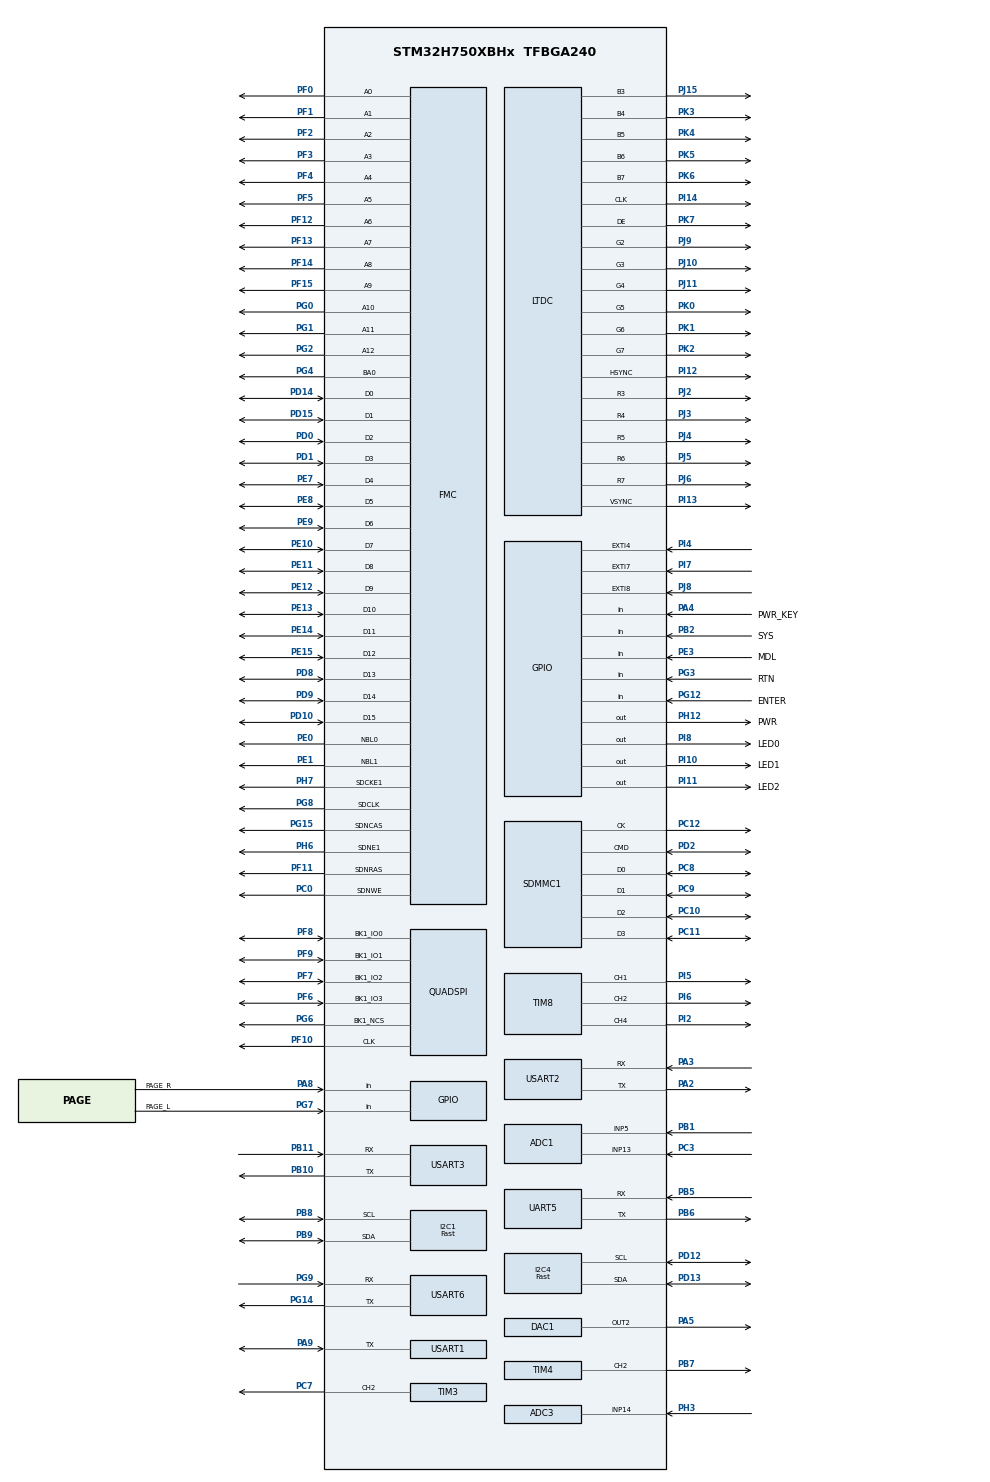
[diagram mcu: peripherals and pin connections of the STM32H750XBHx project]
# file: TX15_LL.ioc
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ADC1.Channel-0\#ChannelRegularConversion=ADC_CHANNEL_5
ADC1.NbrOfConversionFlag=1
ADC1.OffsetNumber-0\#ChannelRegularConversion=ADC_OFFSET_NONE
ADC1.OffsetSignedSaturation-0\#ChannelRegularConversion=DISABLE
ADC1.OversamplingMode=ENABLE
ADC1.Rank-0\#ChannelRegularConversion=1
ADC1.Ratio=16
ADC1.RightBitShift=ADC_RIGHTBITSHIFT_4
ADC1.SamplingTime-0\#ChannelRegularConversion=ADC_SAMPLETIME_1CYCLE_5
ADC1.master=1
ADC3.Channel-2\#ChannelRegularConversion=ADC_CHANNEL_14
ADC3.NbrOfConversionFlag=1
ADC3.OffsetNumber-2\#ChannelRegularConversion=ADC_OFFSET_NONE
ADC3.OffsetSignedSaturation-2\#ChannelRegularConversion=DISABLE
ADC3.Rank-2\#ChannelRegularConversion=1
ADC3.SamplingTime-2\#ChannelRegularConversion=ADC_SAMPLETIME_1CYCLE_5
CORTEX_M7.default_mode_Activation=1
DAC1.DAC_Channel-DAC_OUT2_ExtAndInt=DAC_CHANNEL_2
DAC1.DAC_Trigger-DAC_OUT2_ExtAndInt=DAC_TRIGGER_T6_TRGO
DMA2D.ColorMode=DMA2D_OUTPUT_RGB565
Dma.ADC1.2.Direction=DMA_PERIPH_TO_MEMORY
Dma.ADC1.2.EventEnable=DISABLE
Dma.ADC1.2.FIFOMode=DMA_FIFOMODE_DISABLE
Dma.ADC1.2.Instance=DMA1_Stream2
Dma.ADC1.2.MemDataAlignment=DMA_MDATAALIGN_HALFWORD
Dma.ADC1.2.MemInc=DMA_MINC_ENABLE
Dma.ADC1.2.Mode=DMA_NORMAL
Dma.ADC1.2.PeriphDataAlignment=DMA_PDATAALIGN_HALFWORD
Dma.ADC1.2.PeriphInc=DMA_PINC_DISABLE
Dma.ADC1.2.Polarity=HAL_DMAMUX_REQ_GEN_RISING
Dma.ADC1.2.Priority=DMA_PRIORITY_LOW
Dma.ADC1.2.RequestNumber=1
Dma.ADC1.2.SignalID=NONE
Dma.ADC1.2.SyncEnable=DISABLE
Dma.ADC1.2.SyncPolarity=HAL_DMAMUX_SYNC_NO_EVENT
Dma.ADC1.2.SyncRequestNumber=1
Dma.ADC1.2.SyncSignalID=NONE
Dma.ADC3.3.Direction=DMA_PERIPH_TO_MEMORY
Dma.ADC3.3.EventEnable=DISABLE
Dma.ADC3.3.FIFOMode=DMA_FIFOMODE_DISABLE
Dma.ADC3.3.Instance=DMA1_Stream3
Dma.ADC3.3.MemDataAlignment=DMA_MDATAALIGN_HALFWORD
Dma.ADC3.3.MemInc=DMA_MINC_ENABLE
Dma.ADC3.3.Mode=DMA_NORMAL
Dma.ADC3.3.PeriphDataAlignment=DMA_PDATAALIGN_HALFWORD
Dma.ADC3.3.PeriphInc=DMA_PINC_DISABLE
Dma.ADC3.3.Polarity=HAL_DMAMUX_REQ_GEN_RISING
Dma.ADC3.3.Priority=DMA_PRIORITY_LOW
Dma.ADC3.3.RequestNumber=1
Dma.ADC3.3.SignalID=NONE
Dma.ADC3.3.SyncEnable=DISABLE
Dma.ADC3.3.SyncPolarity=HAL_DMAMUX_SYNC_NO_EVENT
Dma.ADC3.3.SyncRequestNumber=1
Dma.ADC3.3.SyncSignalID=NONE
Dma.DAC1_CH2.4.Direction=DMA_MEMORY_TO_PERIPH
Dma.DAC1_CH2.4.EventEnable=DISABLE
Dma.DAC1_CH2.4.FIFOMode=DMA_FIFOMODE_DISABLE
Dma.DAC1_CH2.4.Instance=DMA1_Stream4
Dma.DAC1_CH2.4.MemDataAlignment=DMA_MDATAALIGN_BYTE
Dma.DAC1_CH2.4.MemInc=DMA_MINC_ENABLE
Dma.DAC1_CH2.4.Mode=DMA_NORMAL
Dma.DAC1_CH2.4.PeriphDataAlignment=DMA_PDATAALIGN_BYTE
Dma.DAC1_CH2.4.PeriphInc=DMA_PINC_DISABLE
Dma.DAC1_CH2.4.Polarity=HAL_DMAMUX_REQ_GEN_RISING
Dma.DAC1_CH2.4.Priority=DMA_PRIORITY_LOW
Dma.DAC1_CH2.4.RequestNumber=1
Dma.DAC1_CH2.4.SignalID=NONE
Dma.DAC1_CH2.4.SyncEnable=DISABLE
Dma.DAC1_CH2.4.SyncPolarity=HAL_DMAMUX_SYNC_NO_EVENT
Dma.DAC1_CH2.4.SyncRequestNumber=1
Dma.DAC1_CH2.4.SyncSignalID=NONE
Dma.Request0=TIM3_CH2
Dma.Request1=TIM8_CH4
Dma.Request2=ADC1
Dma.Request3=ADC3
Dma.Request4=DAC1_CH2
Dma.TIM3_CH2.0.Direction=DMA_PERIPH_TO_MEMORY
Dma.TIM3_CH2.0.EventEnable=DISABLE
Dma.TIM3_CH2.0.FIFOMode=DMA_FIFOMODE_DISABLE
Dma.TIM3_CH2.0.Instance=DMA1_Stream0
Dma.TIM3_CH2.0.MemDataAlignment=DMA_MDATAALIGN_HALFWORD
Dma.TIM3_CH2.0.MemInc=DMA_MINC_ENABLE
Dma.TIM3_CH2.0.Mode=DMA_NORMAL
Dma.TIM3_CH2.0.PeriphDataAlignment=DMA_PDATAALIGN_HALFWORD
Dma.TIM3_CH2.0.PeriphInc=DMA_PINC_DISABLE
Dma.TIM3_CH2.0.Polarity=HAL_DMAMUX_REQ_GEN_RISING
Dma.TIM3_CH2.0.Priority=DMA_PRIORITY_LOW
Dma.TIM3_CH2.0.RequestNumber=1
Dma.TIM3_CH2.0.SignalID=NONE
Dma.TIM3_CH2.0.SyncEnable=DISABLE
Dma.TIM3_CH2.0.SyncPolarity=HAL_DMAMUX_SYNC_NO_EVENT
Dma.TIM3_CH2.0.SyncRequestNumber=1
Dma.TIM3_CH2.0.SyncSignalID=NONE
Dma.TIM8_CH4.1.Direction=DMA_PERIPH_TO_MEMORY
Dma.TIM8_CH4.1.EventEnable=DISABLE
Dma.TIM8_CH4.1.FIFOMode=DMA_FIFOMODE_DISABLE
Dma.TIM8_CH4.1.Instance=DMA1_Stream1
Dma.TIM8_CH4.1.MemDataAlignment=DMA_MDATAALIGN_HALFWORD
Dma.TIM8_CH4.1.MemInc=DMA_MINC_ENABLE
Dma.TIM8_CH4.1.Mode=DMA_NORMAL
Dma.TIM8_CH4.1.PeriphDataAlignment=DMA_PDATAALIGN_HALFWORD
Dma.TIM8_CH4.1.PeriphInc=DMA_PINC_DISABLE
Dma.TIM8_CH4.1.Polarity=HAL_DMAMUX_REQ_GEN_RISING
Dma.TIM8_CH4.1.Priority=DMA_PRIORITY_LOW
Dma.TIM8_CH4.1.RequestNumber=1
Dma.TIM8_CH4.1.SignalID=NONE
Dma.TIM8_CH4.1.SyncEnable=DISABLE
Dma.TIM8_CH4.1.SyncPolarity=HAL_DMAMUX_SYNC_NO_EVENT
Dma.TIM8_CH4.1.SyncRequestNumber=1
Dma.TIM8_CH4.1.SyncSignalID=NONE
FREERTOS.Tasks01=defaultTask,24,128,StartDefaultTask,Default,NULL,Dynamic,NULL,NULL;LedTask,8,128,led_task,Default,NULL,Dynamic,NULL,NULL
I2C1.I2C_Speed_Mode=I2C_Fast
I2C1.Timing=0x00B03FDB
I2C4.I2C_Speed_Mode=I2C_Fast
I2C4.Timing=0x00B03FDB
LTDC.ActiveW=320
LTDC.Alpha_L0=255
LTDC.HBP=20
LTDC.HFP=40
LTDC.HSync=6
LTDC.Layers=0
LTDC.PixelFormat_L0=LTDC_PIXEL_FORMAT_RGB565
LTDC.VBP=10
LTDC.VFP=10
LTDC.VSync=2
LTDC.WindowX1_L0=320
LTDC.WindowY1_L0=480
Mcu.Family=STM32H7
Mcu.Name=STM32H750XBHx
Mcu.Package=TFBGA240
Mdma.MDMA_Channel0.Request0=SDMMC1_DMA_ENDBUFFER
Mdma.MDMA_Channel0.RequestsNb=1
Mdma.MDMA_Channel0.SDMMC1_DMA_ENDBUFFER.0.BlockCount=4
Mdma.MDMA_Channel0.SDMMC1_DMA_ENDBUFFER.0.BlockDataLength=512
Mdma.MDMA_Channel0.SDMMC1_DMA_ENDBUFFER.0.BufferTransferLength=2048
Mdma.MDMA_Channel0.SDMMC1_DMA_ENDBUFFER.0.CircularMode=MDMA_LINEAR_LIST
Mdma.MDMA_Channel0.SDMMC1_DMA_ENDBUFFER.0.DataAlignment=MDMA_DATAALIGN_PACKENABLE
Mdma.MDMA_Channel0.SDMMC1_DMA_ENDBUFFER.0.DestBlockAddressOffset=0
Mdma.MDMA_Channel0.SDMMC1_DMA_ENDBUFFER.0.DestBurst=MDMA_DEST_BURST_4BEATS
Mdma.MDMA_Channel0.SDMMC1_DMA_ENDBUFFER.0.DestDataSize=MDMA_DEST_DATASIZE_WORD
Mdma.MDMA_Channel0.SDMMC1_DMA_ENDBUFFER.0.DestinationInc=MDMA_DEST_INC_WORD
Mdma.MDMA_Channel0.SDMMC1_DMA_ENDBUFFER.0.DstAddress=0
Mdma.MDMA_Channel0.SDMMC1_DMA_ENDBUFFER.0.Endianness=MDMA_LITTLE_ENDIANNESS_PRESERVE
Mdma.MDMA_Channel0.SDMMC1_DMA_ENDBUFFER.0.Instance=MDMA_Channel0
Mdma.MDMA_Channel0.SDMMC1_DMA_ENDBUFFER.0.MaskAddress=0
Mdma.MDMA_Channel0.SDMMC1_DMA_ENDBUFFER.0.MaskData=0
Mdma.MDMA_Channel0.SDMMC1_DMA_ENDBUFFER.0.Priority=MDMA_PRIORITY_LOW
Mdma.MDMA_Channel0.SDMMC1_DMA_ENDBUFFER.0.Rank=First
Mdma.MDMA_Channel0.SDMMC1_DMA_ENDBUFFER.0.SourceBlockAddressOffset=0
Mdma.MDMA_Channel0.SDMMC1_DMA_ENDBUFFER.0.SourceBurst=MDMA_SOURCE_BURST_4BEATS
Mdma.MDMA_Channel0.SDMMC1_DMA_ENDBUFFER.0.SourceDataSize=MDMA_SRC_DATASIZE_WORD
Mdma.MDMA_Channel0.SDMMC1_DMA_ENDBUFFER.0.SourceInc=MDMA_SRC_INC_WORD
Mdma.MDMA_Channel0.SDMMC1_DMA_ENDBUFFER.0.SrcAddress=0
Mdma.MDMA_Channel0.SDMMC1_DMA_ENDBUFFER.0.TransferTriggerMode=MDMA_BUFFER_TRANSFER
Mdma.RequestSet0=MDMA_Channel0
Mdma.RequestSetsNb=1
NVIC.DMA1_Stream0_IRQn=true\:5\:0\:false\:false\:true\:true\:false\:true\:true
NVIC.DMA1_Stream1_IRQn=true\:5\:0\:false\:false\:true\:true\:false\:true\:true
NVIC.DMA1_Stream2_IRQn=true\:5\:0\:false\:false\:true\:true\:false\:true\:true
NVIC.DMA1_Stream3_IRQn=true\:5\:0\:false\:false\:true\:true\:false\:true\:true
NVIC.DMA1_Stream4_IRQn=true\:5\:0\:false\:false\:true\:true\:false\:true\:true
NVIC.EXTI4_IRQn=true\:5\:0\:false\:false\:true\:true\:true\:true\:true
NVIC.EXTI9_5_IRQn=true\:5\:0\:false\:false\:true\:true\:true\:true\:true
NVIC.LTDC_IRQn=true\:5\:0\:false\:false\:true\:true\:true\:true\:true
NVIC.MDMA_IRQn=true\:5\:0\:false\:false\:true\:true\:false\:true\:true
NVIC.PriorityGroup=NVIC_PRIORITYGROUP_4
NVIC.TIM17_IRQn=true\:5\:0\:false\:false\:true\:true\:true\:true\:true
NVIC.TIM1_UP_IRQn=true\:15\:0\:false\:false\:true\:false\:false\:true\:true
NVIC.TIM6_DAC_IRQn=true\:5\:0\:false\:false\:true\:true\:true\:true\:true
NVIC.TIM8_CC_IRQn=true\:5\:0\:false\:false\:true\:true\:true\:true\:true
NVIC.TIM8_UP_TIM13_IRQn=true\:5\:0\:false\:false\:true\:true\:true\:true\:true
NVIC.TimeBase=TIM1_UP_IRQn
NVIC.TimeBaseIP=TIM1
PA10.Signal=S_TIM1_CH3
PA2.Mode=Asynchronous
PA2.Signal=USART2_TX
PA3.Mode=Asynchronous
PA3.Signal=USART2_RX
PA4.GPIO_Label=PWR_KEY
PA4.Signal=GPIO_Input
PA5.Signal=COMP_DAC12_group
PA8.GPIO_Label=PAGE_R
PA8.Signal=GPIO_Input
PA9.Mode=Half_duplex(single_wire_mode)
PA9.Signal=USART1_TX
PB1.Signal=ADCx_INP5
PB10.Mode=Asynchronous
PB10.Signal=USART3_TX
PB11.Mode=Asynchronous
PB11.Signal=USART3_RX
PB2.GPIO_Label=SYS
PB2.Signal=GPIO_Input
PB5.Mode=Asynchronous
PB5.Signal=UART5_RX
PB6.Mode=Asynchronous
PB6.Signal=UART5_TX
PB7.Signal=S_TIM4_CH2
PB8.Mode=I2C
PB8.Signal=I2C1_SCL
PB9.Mode=I2C
PB9.Signal=I2C1_SDA
PC0.Signal=FMC_SDNWE
PC1.Signal=ADCx_INP11
PC10.Mode=SD_4_bits_Wide_bus
PC10.Signal=SDMMC1_D2
PC11.Mode=SD_4_bits_Wide_bus
PC11.Signal=SDMMC1_D3
PC12.Mode=SD_4_bits_Wide_bus
PC12.Signal=SDMMC1_CK
PC2.Signal=ADCx_INP12
PC3.Signal=ADCx_INP13
PC7.Signal=S_TIM3_CH2
PC8.Mode=SD_4_bits_Wide_bus
PC8.Signal=SDMMC1_D0
PC9.Mode=SD_4_bits_Wide_bus
PC9.Signal=SDMMC1_D1
PD0.Signal=FMC_D2_DA2
PD1.Signal=FMC_D3_DA3
PD10.Signal=FMC_D15_DA15
PD12.Mode=I2C
PD12.Signal=I2C4_SCL
PD13.Mode=I2C
PD13.Signal=I2C4_SDA
PD14.Signal=FMC_D0_DA0
PD15.Signal=FMC_D1_DA1
PD2.Mode=SD_4_bits_Wide_bus
PD2.Signal=SDMMC1_CMD
PD8.Signal=FMC_D13_DA13
PD9.Signal=FMC_D14_DA14
PE0.Signal=FMC_NBL0
PE1.Signal=FMC_NBL1
PE10.Signal=FMC_D7_DA7
PE11.Signal=FMC_D8_DA8
PE12.Signal=FMC_D9_DA9
PE13.Signal=FMC_D10_DA10
PE14.Signal=FMC_D11_DA11
PE15.Signal=FMC_D12_DA12
PE3.GPIO_Label=MDL
PE3.Signal=GPIO_Input
PE7.Signal=FMC_D4_DA4
PE8.Signal=FMC_D5_DA5
PE9.Signal=FMC_D6_DA6
PF0.Signal=FMC_A0
PF1.Signal=FMC_A1
PF10.Mode=Single Bank 1
PF10.Signal=QUADSPI_CLK
PF11.Signal=FMC_SDNRAS
PF12.Signal=FMC_A6
PF13.Signal=FMC_A7
PF14.Signal=FMC_A8
PF15.Signal=FMC_A9
PF2.Signal=FMC_A2
PF3.Signal=FMC_A3
PF4.Signal=FMC_A4
PF5.Signal=FMC_A5
PF6.Mode=Single Bank 1
PF6.Signal=QUADSPI_BK1_IO3
PF7.Mode=Single Bank 1
PF7.Signal=QUADSPI_BK1_IO2
PF8.Mode=Single Bank 1
PF8.Signal=QUADSPI_BK1_IO0
PF9.Mode=Single Bank 1
PF9.Signal=QUADSPI_BK1_IO1
PG0.Signal=FMC_A10
PG1.Signal=FMC_A11
PG12.GPIO_Label=ENTER
PG12.Signal=GPIO_Input
PG14.Mode=Asynchronous
PG14.Signal=USART6_TX
PG15.Signal=FMC_SDNCAS
PG2.Signal=FMC_A12
PG3.GPIO_Label=RTN
PG3.Signal=GPIO_Input
PG4.Signal=FMC_A14_BA0
PG5.Signal=FMC_A15_BA1
PG6.Mode=Single Bank 1
PG6.Signal=QUADSPI_BK1_NCS
PG7.GPIO_Label=PAGE_L
PG7.Signal=GPIO_Input
PG8.Signal=FMC_SDCLK
PG9.Mode=Asynchronous
PG9.Signal=USART6_RX
PH0-OSC_IN\ (PH0).Mode=HSE-External-Clock-Source
PH0-OSC_IN\ (PH0).Signal=RCC_OSC_IN
PH12.GPIO_Label=PWR
PH12.Signal=GPIO_Output
PH3.Mode=IN14-Single-Ended
PH3.Signal=ADC3_INP14
PH6.Mode=SdramChipSelect2_1
PH6.Signal=FMC_SDNE1
PH7.Mode=SdramChipSelect2_1
PH7.Signal=FMC_SDCKE1
PI10.GPIO_Label=LED1
PI10.Signal=GPIO_Output
PI11.GPIO_Label=LED2
PI11.Signal=GPIO_Output
PI12.Mode=RGB565
PI12.Signal=LTDC_HSYNC
PI13.Mode=RGB565
PI13.Signal=LTDC_VSYNC
PI14.Mode=RGB565
PI14.Signal=LTDC_CLK
PI2.Signal=S_TIM8_CH4
PI4.Signal=GPXTI4
PI5.Signal=S_TIM8_CH1
PI6.Signal=S_TIM8_CH2
PI7.Signal=GPXTI7
PI8.GPIO_Label=LED0
PI8.Signal=GPIO_Output
PJ1.Signal=LTDC_R2
PJ10.Mode=RGB565
PJ10.Signal=LTDC_G3
PJ11.Mode=RGB565
PJ11.Signal=LTDC_G4
PJ14.Signal=LTDC_B2
PJ15.Mode=RGB565
PJ15.Signal=LTDC_B3
PJ2.Mode=RGB565
PJ2.Signal=LTDC_R3
PJ3.Mode=RGB565
PJ3.Signal=LTDC_R4
PJ4.Mode=RGB565
PJ4.Signal=LTDC_R5
PJ5.Mode=RGB565
PJ5.Signal=LTDC_R6
PJ6.Mode=RGB565
PJ6.Signal=LTDC_R7
PJ8.Signal=GPXTI8
PJ9.Mode=RGB565
PJ9.Signal=LTDC_G2
PK0.Mode=RGB565
PK0.Signal=LTDC_G5
PK1.Mode=RGB565
PK1.Signal=LTDC_G6
PK2.Mode=RGB565
PK2.Signal=LTDC_G7
PK3.Mode=RGB565
PK3.Signal=LTDC_B4
PK4.Mode=RGB565
PK4.Signal=LTDC_B5
PK5.Mode=RGB565
PK5.Signal=LTDC_B6
PK6.Mode=RGB565
PK6.Signal=LTDC_B7
PK7.Mode=RGB565
PK7.Signal=LTDC_DE
ProjectManager.HeapSize=0x200
ProjectManager.StackSize=0x400
ProjectManager.TargetToolchain=MDK-ARM V5.32
QUADSPI.ClockPrescaler=2
QUADSPI.FifoThreshold=8
QUADSPI.FlashSize=23
RCC.ADCCLockSelection=RCC_ADCCLKSOURCE_CLKP
RCC.ADCFreq_Value=64000000
RCC.APB1Freq_Value=120000000
RCC.APB2Freq_Value=120000000
RCC.APB3Freq_Value=120000000
RCC.APB4Freq_Value=120000000
RCC.CortexFreq_Value=480000000
RCC.D1PPRE=RCC_APB3_DIV2
RCC.D2PPRE1=RCC_APB1_DIV2
RCC.D2PPRE2=RCC_APB2_DIV2
RCC.D3PPRE=RCC_APB4_DIV2
RCC.DIVM1=3
RCC.DIVM2=24
RCC.DIVM3=1
RCC.DIVN1=60
RCC.DIVN2=96
RCC.DIVN3=4
RCC.DIVP2=26
RCC.DIVQ1=20
RCC.DIVQ2=4
RCC.DIVR2=1
RCC.DIVR3=18
RCC.EnbaleCSS=false
RCC.FMCCLockSelection=RCC_FMCCLKSOURCE_PLL2
RCC.HCLKFreq_Value=240000000
RCC.HPRE=RCC_HCLK_DIV2
RCC.HSE_VALUE=48000000
RCC.PLL2FRACN=0
RCC.PLL2_VCI_Range-AdvancedSettings=RCC_PLL2VCIRANGE_0
RCC.PLL2_VCO_SEL-AdvancedSettings=RCC_PLL2VCOWIDE
RCC.PLL3FRACN=0
RCC.PLL3_VCI_Range-AdvancedSettings=RCC_PLL3VCIRANGE_0
RCC.PLLFRACN=0
RCC.PLLSourceVirtual=RCC_PLLSOURCE_HSE
RCC.RCC_RTC_Clock_Source_FROM_HSE=RCC_RTCCLKSOURCE_HSE_DIV48
RCC.SYSCLKFreq_VALUE=480000000
RCC.SYSCLKSource=RCC_SYSCLKSOURCE_PLLCLK
RCC.USBFreq_Value=48000000
RTC.WakeUpClock-WakeUp=RTC_WAKEUPCLOCK_CK_SPRE_16BITS
SDMMC1.ClockDiv=2
SH.ADCx_INP11.0=ADC1_INP11
SH.ADCx_INP12.0=ADC1_INP12
SH.ADCx_INP13.0=ADC1_INP13,IN13-Single-Ended
SH.ADCx_INP5.0=ADC1_INP5,IN5-Single-Ended
SH.COMP_DAC12_group.0=DAC1_OUT2,DAC_OUT2_ExtAndInt
SH.FMC_A0.0=FMC_A0,13b-sda1
SH.FMC_A1.0=FMC_A1,13b-sda1
SH.FMC_A10.0=FMC_A10,13b-sda1
SH.FMC_A11.0=FMC_A11,13b-sda1
SH.FMC_A12.0=FMC_A12,13b-sda1
SH.FMC_A14_BA0.0=FMC_BA0,TwoSdramBanks1
SH.FMC_A15_BA1.0=FMC_BA1
SH.FMC_A2.0=FMC_A2,13b-sda1
SH.FMC_A3.0=FMC_A3,13b-sda1
SH.FMC_A4.0=FMC_A4,13b-sda1
SH.FMC_A5.0=FMC_A5,13b-sda1
SH.FMC_A6.0=FMC_A6,13b-sda1
SH.FMC_A7.0=FMC_A7,13b-sda1
SH.FMC_A8.0=FMC_A8,13b-sda1
SH.FMC_A9.0=FMC_A9,13b-sda1
SH.FMC_D0_DA0.0=FMC_D0,sd-16b-d1
SH.FMC_D10_DA10.0=FMC_D10,sd-16b-d1
SH.FMC_D11_DA11.0=FMC_D11,sd-16b-d1
SH.FMC_D12_DA12.0=FMC_D12,sd-16b-d1
SH.FMC_D13_DA13.0=FMC_D13,sd-16b-d1
SH.FMC_D14_DA14.0=FMC_D14,sd-16b-d1
SH.FMC_D15_DA15.0=FMC_D15,sd-16b-d1
SH.FMC_D1_DA1.0=FMC_D1,sd-16b-d1
SH.FMC_D2_DA2.0=FMC_D2,sd-16b-d1
SH.FMC_D3_DA3.0=FMC_D3,sd-16b-d1
SH.FMC_D4_DA4.0=FMC_D4,sd-16b-d1
SH.FMC_D5_DA5.0=FMC_D5,sd-16b-d1
SH.FMC_D6_DA6.0=FMC_D6,sd-16b-d1
SH.FMC_D7_DA7.0=FMC_D7,sd-16b-d1
SH.FMC_D8_DA8.0=FMC_D8,sd-16b-d1
SH.FMC_D9_DA9.0=FMC_D9,sd-16b-d1
SH.FMC_NBL0.0=FMC_NBL0,Sd2ByteEnable1
SH.FMC_NBL1.0=FMC_NBL1,Sd2ByteEnable1
SH.FMC_SDCLK.0=FMC_SDCLK,13b-sda1
SH.FMC_SDNCAS.0=FMC_SDNCAS,13b-sda1
SH.FMC_SDNRAS.0=FMC_SDNRAS,13b-sda1
SH.FMC_SDNWE.0=FMC_SDNWE,13b-sda1
SH.S_TIM1_CH3.0=TIM1_CH3
SH.S_TIM3_CH2.0=TIM3_CH2,PWM Generation2 CH2
SH.S_TIM4_CH2.0=TIM4_CH2,PWM Generation2 CH2
SH.S_TIM8_CH1.0=TIM8_CH1,Output Compare1 CH1
SH.S_TIM8_CH2.0=TIM8_CH2,Output Compare2 CH2
SH.S_TIM8_CH4.0=TIM8_CH4,PWM Generation4 CH4
TIM17.Period=1000
TIM17.Prescaler=4
TIM3.Channel-PWM\ Generation2\ CH2=TIM_CHANNEL_2
TIM3.Prescaler=2
TIM4.Channel-PWM\ Generation2\ CH2=TIM_CHANNEL_2
TIM8.Channel-Output\ Compare1\ CH1=TIM_CHANNEL_1
TIM8.Channel-Output\ Compare2\ CH2=TIM_CHANNEL_2
TIM8.Channel-PWM\ Generation4\ CH4=TIM_CHANNEL_4
USART1.VirtualMode-Half_duplex(single_wire_mode)=VM_ASYNC
USART2.VirtualMode-Asynchronous=VM_ASYNC
USART3.VirtualMode-Asynchronous=VM_ASYNC
USART6.VirtualMode-Asynchronous=VM_ASYNC
VP_DMA2D_VS_DMA2D.Mode=DMA2D_Activate
VP_FREERTOS_VS_CMSIS_V2.Mode=CMSIS_V2
VP_MEMORYMAP_VS_MEMORYMAP.Mode=CurAppReg
VP_RTC_VS_RTC_Activate.Mode=RTC_Enabled
VP_RTC_VS_RTC_WakeUp_intern.Mode=WakeUp
VP_SYS_VS_tim1.Mode=TIM1
VP_TIM17_VS_ClockSourceINT.Mode=Enable_Timer
board=custom

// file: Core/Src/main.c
/* USER CODE BEGIN Header */
/**
  ******************************************************************************
  * @file           : main.c
  * @brief          : Main program body
  ******************************************************************************
  * @attention
  *
  * Copyright (c) 2024 STMicroelectronics.
  * All rights reserved.
  *
  * This software is licensed under terms that can be found in the LICENSE file
  * in the root directory of this software component.
  * If no LICENSE file comes with this software, it is provided AS-IS.
  *
  ******************************************************************************
  */
/* USER CODE END Header */
#include "main.h"
#include "cmsis_os.h"
#include "adc.h"
#include "dac.h"
#include "dma.h"
#include "dma2d.h"
#include "i2c.h"
#include "ltdc.h"
#include "mdma.h"
#include "quadspi.h"
#include "rtc.h"
#include "sdmmc.h"
#include "tim.h"
#include "usart.h"
#include "gpio.h"
#include "fmc.h"

/* USER CODE BEGIN Includes */
#include "bsp_led.h"

/* USER CODE END Includes */

/* USER CODE BEGIN PM */
uint32_t milli_second=0;
uint32_t millis(void)
{
	return milli_second;
}

/* USER CODE END PM */

void SystemClock_Config(void);
void PeriphCommonClock_Config(void);
static void MPU_Config(void);
void MX_FREERTOS_Init(void);

int main(void)
{

  /* MPU Configuration--------------------------------------------------------*/
  MPU_Config();

  /* MCU Configuration--------------------------------------------------------*/

  /* Reset of all peripherals, Initializes the Flash interface and the Systick. */
  HAL_Init();

  /* Configure the system clock */
  SystemClock_Config();

  /* Configure the peripherals common clocks */
  PeriphCommonClock_Config();

  /* Initialize all configured peripherals */
  MX_GPIO_Init();
  MX_DMA_Init();
  MX_MDMA_Init();
  MX_UART5_Init();
  MX_USART2_UART_Init();
  MX_USART3_UART_Init();
  MX_USART6_UART_Init();
  MX_LTDC_Init();
  MX_DMA2D_Init();
  MX_I2C4_Init();
  MX_ADC1_Init();
  MX_ADC3_Init();
  MX_FMC_Init();
  MX_QUADSPI_Init();
  MX_TIM8_Init();
  MX_TIM3_Init();
  MX_TIM17_Init();
  MX_SDMMC1_SD_Init();
  MX_RTC_Init();
  MX_TIM4_Init();
  MX_USART1_UART_Init();
  MX_I2C1_Init();
  MX_DAC1_Init();

  /* Init scheduler */
  osKernelInitialize();  /* Call init function for freertos objects (in cmsis_os2.c) */
  MX_FREERTOS_Init();

  /* Start scheduler */
  osKernelStart();

  /* We should never get here as control is now taken by the scheduler */

  /* Infinite loop */
  while (1)
  {

    /* USER CODE BEGIN 3 */
	  LL_GPIO_TogglePin(LED1_GPIO_Port, LED0_Pin);
	  LL_mDelay(300);
  }
  /* USER CODE END 3 */
}

void SystemClock_Config(void)
{
  LL_FLASH_SetLatency(LL_FLASH_LATENCY_4);
  while(LL_FLASH_GetLatency()!= LL_FLASH_LATENCY_4)
  {
  }
  LL_PWR_ConfigSupply(LL_PWR_LDO_SUPPLY);
  LL_PWR_SetRegulVoltageScaling(LL_PWR_REGU_VOLTAGE_SCALE0);
  while (LL_PWR_IsActiveFlag_VOS() == 0)
  {
  }
  LL_RCC_HSE_EnableBypass();
  LL_RCC_HSE_Enable();

   /* Wait till HSE is ready */
  while(LL_RCC_HSE_IsReady() != 1)
  {

  }
  LL_RCC_HSI_Enable();

   /* Wait till HSI is ready */
  while(LL_RCC_HSI_IsReady() != 1)
  {

  }
  LL_RCC_HSI_SetCalibTrimming(64);
  LL_RCC_HSI_SetDivider(LL_RCC_HSI_DIV1);
  LL_RCC_LSI_Enable();

   /* Wait till LSI is ready */
  while(LL_RCC_LSI_IsReady() != 1)
  {

  }
  LL_PWR_EnableBkUpAccess();
  LL_RCC_PLL_SetSource(LL_RCC_PLLSOURCE_HSE);
  LL_RCC_PLL1P_Enable();
  LL_RCC_PLL1Q_Enable();
  LL_RCC_PLL1_SetVCOInputRange(LL_RCC_PLLINPUTRANGE_8_16);
  LL_RCC_PLL1_SetVCOOutputRange(LL_RCC_PLLVCORANGE_WIDE);
  LL_RCC_PLL1_SetM(3);
  LL_RCC_PLL1_SetN(60);
  LL_RCC_PLL1_SetP(2);
  LL_RCC_PLL1_SetQ(20);
  LL_RCC_PLL1_SetR(2);
  LL_RCC_PLL1_Enable();

   /* Wait till PLL is ready */
  while(LL_RCC_PLL1_IsReady() != 1)
  {
  }

   /* Intermediate AHB prescaler 2 when target frequency clock is higher than 80 MHz */
   LL_RCC_SetAHBPrescaler(LL_RCC_AHB_DIV_2);

  LL_RCC_SetSysClkSource(LL_RCC_SYS_CLKSOURCE_PLL1);

   /* Wait till System clock is ready */
  while(LL_RCC_GetSysClkSource() != LL_RCC_SYS_CLKSOURCE_STATUS_PLL1)
  {

  }
  LL_RCC_SetSysPrescaler(LL_RCC_SYSCLK_DIV_1);
  LL_RCC_SetAHBPrescaler(LL_RCC_AHB_DIV_2);
  LL_RCC_SetAPB1Prescaler(LL_RCC_APB1_DIV_2);
  LL_RCC_SetAPB2Prescaler(LL_RCC_APB2_DIV_2);
  LL_RCC_SetAPB3Prescaler(LL_RCC_APB3_DIV_2);
  LL_RCC_SetAPB4Prescaler(LL_RCC_APB4_DIV_2);
  LL_SetSystemCoreClock(480000000);

   /* Update the time base */
  if (HAL_InitTick (TICK_INT_PRIORITY) != HAL_OK)
  {
    Error_Handler();
  }
}

void PeriphCommonClock_Config(void)
{
  LL_RCC_PLL2R_Enable();
  LL_RCC_PLL2_SetVCOInputRange(LL_RCC_PLLINPUTRANGE_2_4);
  LL_RCC_PLL2_SetVCOOutputRange(LL_RCC_PLLVCORANGE_WIDE);
  LL_RCC_PLL2_SetM(24);
  LL_RCC_PLL2_SetN(96);
  LL_RCC_PLL2_SetP(26);
  LL_RCC_PLL2_SetQ(4);
  LL_RCC_PLL2_SetR(1);
  LL_RCC_PLL2_Enable();

   /* Wait till PLL is ready */
  while(LL_RCC_PLL2_IsReady() != 1)
  {
  }

  LL_RCC_PLL3R_Enable();
  LL_RCC_PLL3_SetVCOInputRange(LL_RCC_PLLINPUTRANGE_8_16);
  LL_RCC_PLL3_SetVCOOutputRange(LL_RCC_PLLVCORANGE_WIDE);
  LL_RCC_PLL3_SetM(1);
  LL_RCC_PLL3_SetN(4);
  LL_RCC_PLL3_SetP(2);
  LL_RCC_PLL3_SetQ(2);
  LL_RCC_PLL3_SetR(18);
  LL_RCC_PLL3_Enable();

   /* Wait till PLL is ready */
  while(LL_RCC_PLL3_IsReady() != 1)
  {
  }

  LL_RCC_SetCLKPClockSource(LL_RCC_CLKP_CLKSOURCE_HSI);
}

 /* MPU Configuration */

void MPU_Config(void)
{

  /* Disables the MPU */
  LL_MPU_Disable();

  /** Initializes and configures the Region and the memory to be protected
  */
  LL_MPU_ConfigRegion(LL_MPU_REGION_NUMBER0, 0x87, 0x0, LL_MPU_REGION_SIZE_4GB|LL_MPU_TEX_LEVEL0|LL_MPU_REGION_NO_ACCESS|LL_MPU_INSTRUCTION_ACCESS_DISABLE|LL_MPU_ACCESS_SHAREABLE|LL_MPU_ACCESS_NOT_CACHEABLE|LL_MPU_ACCESS_NOT_BUFFERABLE);
  /* Enables the MPU */
  LL_MPU_Enable(LL_MPU_CTRL_PRIVILEGED_DEFAULT);

}

void HAL_TIM_PeriodElapsedCallback(TIM_HandleTypeDef *htim)
{
  if (htim->Instance == TIM1)
  {
    HAL_IncTick();
  }
}

void Error_Handler(void)
{
  __disable_irq();
  while (1)
  {
  }
}

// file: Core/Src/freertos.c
/* USER CODE BEGIN Header */
/**
  ******************************************************************************
  * File Name          : freertos.c
  * Description        : Code for freertos applications
  ******************************************************************************
  * @attention
  *
  * Copyright (c) 2025 STMicroelectronics.
  * All rights reserved.
  *
  * This software is licensed under terms that can be found in the LICENSE file
  * in the root directory of this software component.
  * If no LICENSE file comes with this software, it is provided AS-IS.
  *
  ******************************************************************************
  */
/* USER CODE END Header */

#include "FreeRTOS.h"
#include "task.h"
#include "main.h"
#include "cmsis_os.h"

/* Definitions for defaultTask */
osThreadId_t defaultTaskHandle;
const osThreadAttr_t defaultTask_attributes = {
  .name = "defaultTask",
  .stack_size = 128 * 4,
  .priority = (osPriority_t) osPriorityNormal,
};
/* Definitions for LedTask */
osThreadId_t LedTaskHandle;
const osThreadAttr_t LedTask_attributes = {
  .name = "LedTask",
  .stack_size = 128 * 4,
  .priority = (osPriority_t) osPriorityLow,
};

void StartDefaultTask(void *argument);
void led_task(void *argument);

void MX_FREERTOS_Init(void); /* (MISRA C 2004 rule 8.1) */

void MX_FREERTOS_Init(void) {

  /* Create the thread(s) */
  /* creation of defaultTask */
  defaultTaskHandle = osThreadNew(StartDefaultTask, NULL, &defaultTask_attributes);

  /* creation of LedTask */
  LedTaskHandle = osThreadNew(led_task, NULL, &LedTask_attributes);

}

void StartDefaultTask(void *argument)
{
  for(;;)
  {
    osDelay(1);
  }
}

void led_task(void *argument)
{
  for(;;)
  {
    osDelay(1);
  }
}
